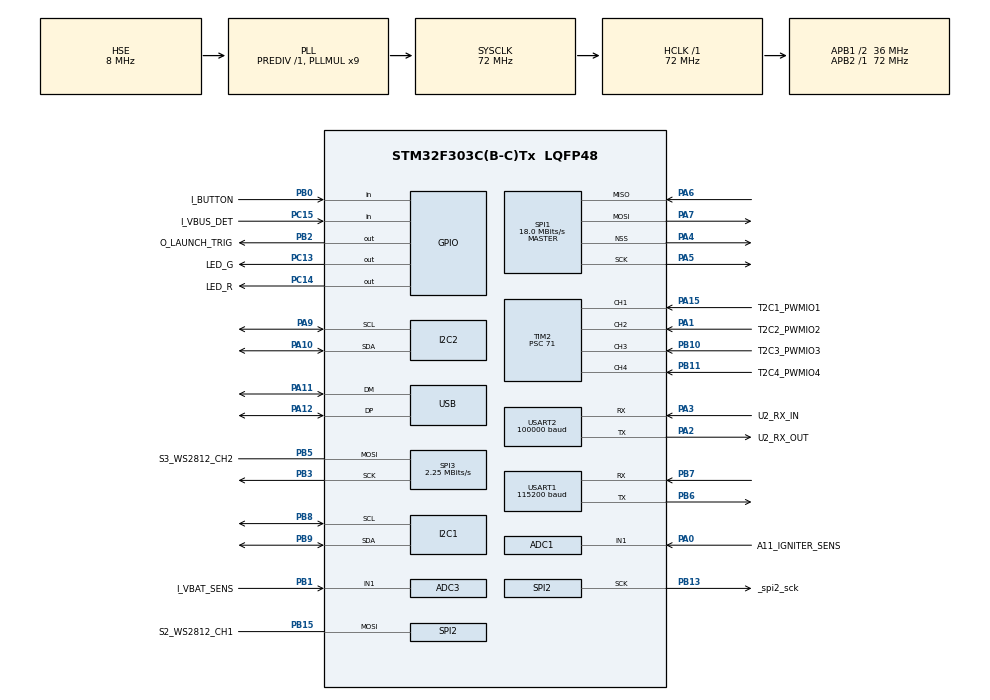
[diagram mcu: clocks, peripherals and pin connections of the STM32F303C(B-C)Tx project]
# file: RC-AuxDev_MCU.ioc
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ADC1.Channel-0\#ChannelRegularConversion=ADC_CHANNEL_TEMPSENSOR
ADC1.NbrOfConversionFlag=1
ADC1.Offset-0\#ChannelRegularConversion=0
ADC1.OffsetNumber-0\#ChannelRegularConversion=ADC_OFFSET_NONE
ADC1.Rank-0\#ChannelRegularConversion=1
ADC1.SamplingTime-0\#ChannelRegularConversion=ADC_SAMPLETIME_1CYCLE_5
ADC1.master=1
ADC3.Channel-0\#ChannelRegularConversion=ADC_CHANNEL_1
ADC3.NbrOfConversionFlag=1
ADC3.Offset-0\#ChannelRegularConversion=0
ADC3.OffsetNumber-0\#ChannelRegularConversion=ADC_OFFSET_NONE
ADC3.Rank-0\#ChannelRegularConversion=1
ADC3.SamplingTime-0\#ChannelRegularConversion=ADC_SAMPLETIME_1CYCLE_5
ADC3.SamplingTimeOPAMP-0\#ChannelRegularConversion=ADC_SAMPLETIME_61CYCLES_5
ADC3.master=1
Dma.Request0=SPI2_TX
Dma.Request1=SPI3_TX
Dma.Request2=USART2_RX
Dma.SPI2_TX.0.Direction=DMA_MEMORY_TO_PERIPH
Dma.SPI2_TX.0.Instance=DMA1_Channel5
Dma.SPI2_TX.0.MemDataAlignment=DMA_MDATAALIGN_BYTE
Dma.SPI2_TX.0.MemInc=DMA_MINC_ENABLE
Dma.SPI2_TX.0.Mode=DMA_NORMAL
Dma.SPI2_TX.0.PeriphDataAlignment=DMA_PDATAALIGN_BYTE
Dma.SPI2_TX.0.PeriphInc=DMA_PINC_DISABLE
Dma.SPI2_TX.0.Priority=DMA_PRIORITY_LOW
Dma.SPI3_TX.1.Direction=DMA_MEMORY_TO_PERIPH
Dma.SPI3_TX.1.Instance=DMA2_Channel2
Dma.SPI3_TX.1.MemDataAlignment=DMA_MDATAALIGN_BYTE
Dma.SPI3_TX.1.MemInc=DMA_MINC_ENABLE
Dma.SPI3_TX.1.Mode=DMA_NORMAL
Dma.SPI3_TX.1.PeriphDataAlignment=DMA_PDATAALIGN_BYTE
Dma.SPI3_TX.1.PeriphInc=DMA_PINC_DISABLE
Dma.SPI3_TX.1.Priority=DMA_PRIORITY_LOW
Dma.USART2_RX.2.Direction=DMA_PERIPH_TO_MEMORY
Dma.USART2_RX.2.Instance=DMA1_Channel6
Dma.USART2_RX.2.MemDataAlignment=DMA_MDATAALIGN_BYTE
Dma.USART2_RX.2.MemInc=DMA_MINC_ENABLE
Dma.USART2_RX.2.Mode=DMA_NORMAL
Dma.USART2_RX.2.PeriphDataAlignment=DMA_PDATAALIGN_BYTE
Dma.USART2_RX.2.PeriphInc=DMA_PINC_DISABLE
Dma.USART2_RX.2.Priority=DMA_PRIORITY_LOW
I2C1.Timing=0x10C18DCC
I2C2.Timing=0x10C18DCC
Mcu.Family=STM32F3
Mcu.Name=STM32F303C(B-C)Tx
Mcu.Package=LQFP48
NVIC.DMA1_Channel5_IRQn=true\:0\:0\:false\:false\:true\:true\:true\:true
NVIC.DMA1_Channel6_IRQn=true\:0\:0\:false\:false\:true\:true\:true\:true
NVIC.DMA2_Channel2_IRQn=true\:0\:0\:false\:false\:true\:true\:true\:true
NVIC.PriorityGroup=NVIC_PRIORITYGROUP_4
NVIC.TIM1_BRK_TIM15_IRQn=true\:0\:0\:false\:false\:true\:true\:true\:true
NVIC.TIM2_IRQn=true\:0\:0\:false\:false\:true\:true\:true\:true
NVIC.USART1_IRQn=true\:0\:0\:false\:false\:true\:true\:true\:true
NVIC.USART2_IRQn=true\:0\:0\:false\:false\:true\:true\:true\:true
NVIC.USB_LP_CAN_RX0_IRQn=true\:0\:0\:false\:false\:true\:false\:true\:true
PA0.GPIO_Label=A11_IGNITER_SENS
PA0.Mode=IN1-Single-Ended
PA0.Signal=ADC1_IN1
PA1.GPIO_Label=T2C2_PWMIO2
PA1.GPIO_PuPd=GPIO_PULLDOWN
PA1.Signal=S_TIM2_CH2
PA10.Mode=I2C
PA10.Signal=I2C2_SDA
PA11.Mode=Device
PA11.Signal=USB_DM
PA12.Mode=Device
PA12.Signal=USB_DP
PA13.Mode=Serial_Wire
PA13.Signal=SYS_JTMS-SWDIO
PA13.Stacked=true
PA14.Mode=Serial_Wire
PA14.Signal=SYS_JTCK-SWCLK
PA14.Stacked=true
PA15.GPIO_Label=T2C1_PWMIO1
PA15.GPIO_PuPd=GPIO_PULLDOWN
PA15.Signal=S_TIM2_CH1_ETR
PA2.GPIO_Label=U2_RX_OUT
PA2.Mode=Asynchronous
PA2.Signal=USART2_TX
PA2.Stacked=true
PA3.GPIO_Label=U2_RX_IN
PA3.Signal=SharedStack_PA3
PA3.Stacked=true
PA4.Mode=NSS_Signal_Hard_Output
PA4.Signal=SPI1_NSS
PA5.Mode=Full_Duplex_Master
PA5.Signal=SPI1_SCK
PA6.Mode=Full_Duplex_Master
PA6.Signal=SPI1_MISO
PA7.Mode=Full_Duplex_Master
PA7.Signal=SPI1_MOSI
PA9.Mode=I2C
PA9.Signal=I2C2_SCL
PB0.GPIO_Label=I_BUTTON
PB0.Signal=GPIO_Input
PB1.GPIO_Label=I_VBAT_SENS
PB1.Mode=IN1-Single-Ended
PB1.Signal=ADC3_IN1
PB10.GPIO_Label=T2C3_PWMIO3
PB10.GPIO_PuPd=GPIO_PULLDOWN
PB10.Signal=S_TIM2_CH3
PB11.GPIO_Label=T2C4_PWMIO4
PB11.GPIO_PuPd=GPIO_PULLDOWN
PB11.Signal=S_TIM2_CH4
PB13.GPIO_Label=_spi2_sck
PB13.Mode=Simplex_Bidirectional_Master
PB13.Signal=SPI2_SCK
PB13.Stacked=true
PB15.GPIO_Label=S2_WS2812_CH1
PB15.Mode=Simplex_Bidirectional_Master
PB15.Signal=SPI2_MOSI
PB2.GPIO_Label=O_LAUNCH_TRIG
PB2.GPIO_PuPd=GPIO_PULLDOWN
PB2.Signal=GPIO_Output
PB3.Signal=SharedStack_PB3
PB3.Stacked=true
PB5.GPIO_Label=S3_WS2812_CH2
PB5.Mode=Simplex_Bidirectional_Master
PB5.Signal=SPI3_MOSI
PB6.Mode=Asynchronous
PB6.Signal=USART1_TX
PB7.Mode=Asynchronous
PB7.Signal=USART1_RX
PB8.Mode=I2C
PB8.Signal=I2C1_SCL
PB9.Mode=I2C
PB9.Signal=I2C1_SDA
PC13.GPIO_Label=LED_G
PC13.GPIO_ModeDefaultOutputPP=GPIO_MODE_OUTPUT_OD
PC13.GPIO_PuPd=GPIO_NOPULL
PC13.Signal=GPIO_Output
PC14-OSC32_IN.GPIO_Label=LED_R
PC14-OSC32_IN.GPIO_ModeDefaultOutputPP=GPIO_MODE_OUTPUT_OD
PC14-OSC32_IN.GPIO_PuPd=GPIO_NOPULL
PC14-OSC32_IN.Signal=GPIO_Output
PC15-OSC32_OUT.GPIO_Label=I_VBUS_DET
PC15-OSC32_OUT.GPIO_PuPd=GPIO_PULLDOWN
PC15-OSC32_OUT.Signal=GPIO_Input
PF0-OSC_IN.Mode=HSE-External-Oscillator
PF0-OSC_IN.Signal=RCC_OSC_IN
PF1-OSC_OUT.Mode=HSE-External-Oscillator
PF1-OSC_OUT.Signal=RCC_OSC_OUT
ProjectManager.HeapSize=0x200
ProjectManager.StackSize=0x400
ProjectManager.TargetToolchain=CMake
RCC.AHBFreq_Value=72000000
RCC.APB1CLKDivider=RCC_HCLK_DIV2
RCC.APB1Freq_Value=36000000
RCC.APB1TimFreq_Value=72000000
RCC.APB2Freq_Value=72000000
RCC.APB2TimFreq_Value=72000000
RCC.CortexFreq_Value=72000000
RCC.HCLKFreq_Value=72000000
RCC.HSE_VALUE=8000000
RCC.HSI_VALUE=8000000
RCC.I2c1ClockSelection=RCC_I2C1CLKSOURCE_SYSCLK
RCC.I2c2ClockSelection=RCC_I2C2CLKSOURCE_SYSCLK
RCC.LSE_VALUE=32768
RCC.PLLMUL=RCC_PLL_MUL9
RCC.PRESCALERUSB=RCC_USBCLKSOURCE_PLL_DIV1_5
RCC.SYSCLKFreq_VALUE=72000000
RCC.SYSCLKSourceVirtual=RCC_SYSCLKSOURCE_PLLCLK
RCC.USBFreq_Value=48000000
RCC.Usart1ClockSelection=RCC_USART1CLKSOURCE_SYSCLK
RCC.Usart2ClockSelection=RCC_USART2CLKSOURCE_SYSCLK
RCC.Usart3ClockSelection=RCC_USART3CLKSOURCE_SYSCLK
SH.S_TIM2_CH1_ETR.0=TIM2_CH1,Input_Capture1_from_TI1
SH.S_TIM2_CH2.0=TIM2_CH2,Input_Capture2_from_TI2
SH.S_TIM2_CH3.0=TIM2_CH3,Input_Capture3_from_TI3
SH.S_TIM2_CH4.0=TIM2_CH4,Input_Capture4_from_TI4
SH.SharedStack_PA3.0=TIM15_CH2
SH.SharedStack_PA3.1=USART2_RX,Asynchronous
SH.SharedStack_PB3.0=SYS_JTDO-TRACESWO
SH.SharedStack_PB3.1=SPI3_SCK,Simplex_Bidirectional_Master
SPI1.BaudRatePrescaler=SPI_BAUDRATEPRESCALER_4
SPI1.CalculateBaudRate=18.0 MBits/s
SPI1.Direction=SPI_DIRECTION_2LINES
SPI1.Mode=SPI_MODE_MASTER
SPI1.VirtualNSS=VM_NSSHARD
SPI1.VirtualType=VM_MASTER
SPI2.BaudRatePrescaler=SPI_BAUDRATEPRESCALER_16
SPI2.CalculateBaudRate=2.25 MBits/s
SPI2.DataSize=SPI_DATASIZE_8BIT
SPI2.Direction=SPI_DIRECTION_1LINE
SPI2.Mode=SPI_MODE_MASTER
SPI2.NSSPMode=SPI_NSS_PULSE_DISABLE
SPI2.VirtualType=VM_MASTER
SPI3.BaudRatePrescaler=SPI_BAUDRATEPRESCALER_16
SPI3.CalculateBaudRate=2.25 MBits/s
SPI3.DataSize=SPI_DATASIZE_8BIT
SPI3.Direction=SPI_DIRECTION_1LINE
SPI3.Mode=SPI_MODE_MASTER
SPI3.NSSPMode=SPI_NSS_PULSE_DISABLE
SPI3.VirtualType=VM_MASTER
TIM15.Channel-Output\ Compare2\ No\ Output=TIM_CHANNEL_2
TIM15.Prescaler=71
TIM2.Channel-Input_Capture1_from_TI1=TIM_CHANNEL_1
TIM2.Channel-Input_Capture2_from_TI2=TIM_CHANNEL_2
TIM2.Channel-Input_Capture3_from_TI3=TIM_CHANNEL_3
TIM2.Channel-Input_Capture4_from_TI4=TIM_CHANNEL_4
TIM2.Prescaler=71
USART1.BaudRate=115200
USART1.VirtualMode-Asynchronous=VM_ASYNC
USART2.BaudRate=100000
USART2.Mode=MODE_RX
USART2.Parity=PARITY_EVEN
USART2.RxPinLevelInvertParam=ADVFEATURE_RXINV_ENABLE
USART2.StopBits=STOPBITS_2
USART2.VirtualMode-Asynchronous=VM_ASYNC
USART2.WordLength=WORDLENGTH_9B
USB_DEVICE.CLASS_NAME_FS=CDC
USB_DEVICE.VirtualMode=Cdc
USB_DEVICE.VirtualModeFS=Cdc_FS
VP_ADC1_TempSens_Input.Mode=IN-TempSens
VP_CRC_VS_CRC.Mode=CRC_Activate
VP_RTC_VS_RTC_Activate.Mode=RTC_Enabled
VP_TIM15_VS_ClockSourceINT.Mode=Internal
VP_TIM15_VS_no_output2.Mode=Output Compare2 No Output
VP_TIM2_VS_ClockSourceINT.Mode=Internal
VP_USB_DEVICE_VS_USB_DEVICE_CDC_FS.Mode=CDC_FS
board=custom

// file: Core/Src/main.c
/* USER CODE BEGIN Header */
/**
  ******************************************************************************
  * @file           : main.c
  * @brief          : Main program body
  ******************************************************************************
  * @attention
  *
  * Copyright (c) 2026 STMicroelectronics.
  * All rights reserved.
  *
  * This software is licensed under terms that can be found in the LICENSE file
  * in the root directory of this software component.
  * If no LICENSE file comes with this software, it is provided AS-IS.
  *
  ******************************************************************************
  */
/* USER CODE END Header */
#include "main.h"
#include "usb_device.h"

ADC_HandleTypeDef hadc1;
ADC_HandleTypeDef hadc3;

CRC_HandleTypeDef hcrc;

I2C_HandleTypeDef hi2c1;
I2C_HandleTypeDef hi2c2;

RTC_HandleTypeDef hrtc;

SPI_HandleTypeDef hspi1;
SPI_HandleTypeDef hspi2;
SPI_HandleTypeDef hspi3;
DMA_HandleTypeDef hdma_spi2_tx;
DMA_HandleTypeDef hdma_spi3_tx;

TIM_HandleTypeDef htim2;
TIM_HandleTypeDef htim15;

UART_HandleTypeDef huart1;
UART_HandleTypeDef huart2;
DMA_HandleTypeDef hdma_usart2_rx;

/* USER CODE BEGIN PV */

// MYCUST: code entry points
void main_loop();

/* USER CODE END PV */

void SystemClock_Config(void);
static void MX_GPIO_Init(void);
static void MX_DMA_Init(void);
static void MX_USART1_UART_Init(void);
static void MX_ADC1_Init(void);
static void MX_RTC_Init(void);
static void MX_SPI1_Init(void);
static void MX_I2C1_Init(void);
static void MX_TIM2_Init(void);
static void MX_SPI2_Init(void);
static void MX_I2C2_Init(void);
static void MX_SPI3_Init(void);
static void MX_TIM15_Init(void);
static void MX_CRC_Init(void);
static void MX_USART2_UART_Init(void);
static void MX_ADC3_Init(void);

int main(void)
{

  /* MCU Configuration--------------------------------------------------------*/

  /* Reset of all peripherals, Initializes the Flash interface and the Systick. */
  HAL_Init();

  /* Configure the system clock */
  SystemClock_Config();

  /* USER CODE BEGIN SysInit */

  // MYCUST: Force USB re-enumeration by pulling D+ low
  __HAL_RCC_GPIOA_CLK_ENABLE();
  GPIO_InitTypeDef GPIO_InitStruct = {0};
  GPIO_InitStruct.Pin = GPIO_PIN_12;  // USB D+ pin
  GPIO_InitStruct.Mode = GPIO_MODE_OUTPUT_PP;
  GPIO_InitStruct.Pull = GPIO_NOPULL;
  GPIO_InitStruct.Speed = GPIO_SPEED_FREQ_LOW;
  HAL_GPIO_Init(GPIOA, &GPIO_InitStruct);
  HAL_GPIO_WritePin(GPIOA, GPIO_PIN_12, GPIO_PIN_RESET);  // Pull D+ low
  HAL_Delay(50);  // Hold low for 50ms to ensure host detects disconnect

  /* USER CODE END SysInit */

  /* Initialize all configured peripherals */
  MX_GPIO_Init();
  MX_DMA_Init();
  MX_USART1_UART_Init();
  MX_USB_DEVICE_Init();
  MX_ADC1_Init();
  MX_RTC_Init();
  MX_SPI1_Init();
  MX_I2C1_Init();
  MX_TIM2_Init();
  MX_SPI2_Init();
  MX_I2C2_Init();
  MX_SPI3_Init();
  MX_TIM15_Init();
  MX_CRC_Init();
  MX_USART2_UART_Init();
  MX_ADC3_Init();
  /* USER CODE BEGIN 2 */

  // MYCUST: entry point
  main_loop();

  /* USER CODE END 2 */

  /* Infinite loop */
  while (1)
  {

  }
}

void SystemClock_Config(void)
{
  RCC_OscInitTypeDef RCC_OscInitStruct = {0};
  RCC_ClkInitTypeDef RCC_ClkInitStruct = {0};
  RCC_PeriphCLKInitTypeDef PeriphClkInit = {0};

  /** Initializes the RCC Oscillators according to the specified parameters
  * in the RCC_OscInitTypeDef structure.
  */
  RCC_OscInitStruct.OscillatorType = RCC_OSCILLATORTYPE_LSI|RCC_OSCILLATORTYPE_HSE;
  RCC_OscInitStruct.HSEState = RCC_HSE_ON;
  RCC_OscInitStruct.HSEPredivValue = RCC_HSE_PREDIV_DIV1;
  RCC_OscInitStruct.HSIState = RCC_HSI_ON;
  RCC_OscInitStruct.LSIState = RCC_LSI_ON;
  RCC_OscInitStruct.PLL.PLLState = RCC_PLL_ON;
  RCC_OscInitStruct.PLL.PLLSource = RCC_PLLSOURCE_HSE;
  RCC_OscInitStruct.PLL.PLLMUL = RCC_PLL_MUL9;
  if (HAL_RCC_OscConfig(&RCC_OscInitStruct) != HAL_OK)
  {
    Error_Handler();
  }

  /** Initializes the CPU, AHB and APB buses clocks
  */
  RCC_ClkInitStruct.ClockType = RCC_CLOCKTYPE_HCLK|RCC_CLOCKTYPE_SYSCLK
                              |RCC_CLOCKTYPE_PCLK1|RCC_CLOCKTYPE_PCLK2;
  RCC_ClkInitStruct.SYSCLKSource = RCC_SYSCLKSOURCE_PLLCLK;
  RCC_ClkInitStruct.AHBCLKDivider = RCC_SYSCLK_DIV1;
  RCC_ClkInitStruct.APB1CLKDivider = RCC_HCLK_DIV2;
  RCC_ClkInitStruct.APB2CLKDivider = RCC_HCLK_DIV1;

  if (HAL_RCC_ClockConfig(&RCC_ClkInitStruct, FLASH_LATENCY_2) != HAL_OK)
  {
    Error_Handler();
  }
  PeriphClkInit.PeriphClockSelection = RCC_PERIPHCLK_USB|RCC_PERIPHCLK_USART1
                              |RCC_PERIPHCLK_USART2|RCC_PERIPHCLK_I2C1
                              |RCC_PERIPHCLK_I2C2|RCC_PERIPHCLK_RTC
                              |RCC_PERIPHCLK_ADC12|RCC_PERIPHCLK_ADC34;
  PeriphClkInit.Usart1ClockSelection = RCC_USART1CLKSOURCE_SYSCLK;
  PeriphClkInit.Usart2ClockSelection = RCC_USART2CLKSOURCE_SYSCLK;
  PeriphClkInit.Adc12ClockSelection = RCC_ADC12PLLCLK_DIV1;
  PeriphClkInit.Adc34ClockSelection = RCC_ADC34PLLCLK_DIV1;
  PeriphClkInit.I2c1ClockSelection = RCC_I2C1CLKSOURCE_SYSCLK;
  PeriphClkInit.I2c2ClockSelection = RCC_I2C2CLKSOURCE_SYSCLK;
  PeriphClkInit.RTCClockSelection = RCC_RTCCLKSOURCE_LSI;
  PeriphClkInit.USBClockSelection = RCC_USBCLKSOURCE_PLL_DIV1_5;
  if (HAL_RCCEx_PeriphCLKConfig(&PeriphClkInit) != HAL_OK)
  {
    Error_Handler();
  }
}

static void MX_ADC1_Init(void)
{

  ADC_MultiModeTypeDef multimode = {0};
  ADC_ChannelConfTypeDef sConfig = {0};

  /** Common config
  */
  hadc1.Instance = ADC1;
  hadc1.Init.ClockPrescaler = ADC_CLOCK_ASYNC_DIV1;
  hadc1.Init.Resolution = ADC_RESOLUTION_12B;
  hadc1.Init.ScanConvMode = ADC_SCAN_DISABLE;
  hadc1.Init.ContinuousConvMode = DISABLE;
  hadc1.Init.DiscontinuousConvMode = DISABLE;
  hadc1.Init.ExternalTrigConvEdge = ADC_EXTERNALTRIGCONVEDGE_NONE;
  hadc1.Init.ExternalTrigConv = ADC_SOFTWARE_START;
  hadc1.Init.DataAlign = ADC_DATAALIGN_RIGHT;
  hadc1.Init.NbrOfConversion = 1;
  hadc1.Init.DMAContinuousRequests = DISABLE;
  hadc1.Init.EOCSelection = ADC_EOC_SINGLE_CONV;
  hadc1.Init.LowPowerAutoWait = DISABLE;
  hadc1.Init.Overrun = ADC_OVR_DATA_OVERWRITTEN;
  if (HAL_ADC_Init(&hadc1) != HAL_OK)
  {
    Error_Handler();
  }

  /** Configure the ADC multi-mode
  */
  multimode.Mode = ADC_MODE_INDEPENDENT;
  if (HAL_ADCEx_MultiModeConfigChannel(&hadc1, &multimode) != HAL_OK)
  {
    Error_Handler();
  }

  /** Configure Regular Channel
  */
  sConfig.Channel = ADC_CHANNEL_TEMPSENSOR;
  sConfig.Rank = ADC_REGULAR_RANK_1;
  sConfig.SingleDiff = ADC_SINGLE_ENDED;
  sConfig.SamplingTime = ADC_SAMPLETIME_1CYCLE_5;
  sConfig.OffsetNumber = ADC_OFFSET_NONE;
  sConfig.Offset = 0;
  if (HAL_ADC_ConfigChannel(&hadc1, &sConfig) != HAL_OK)
  {
    Error_Handler();
  }

}

static void MX_ADC3_Init(void)
{

  ADC_MultiModeTypeDef multimode = {0};
  ADC_ChannelConfTypeDef sConfig = {0};

  /** Common config
  */
  hadc3.Instance = ADC3;
  hadc3.Init.ClockPrescaler = ADC_CLOCK_ASYNC_DIV1;
  hadc3.Init.Resolution = ADC_RESOLUTION_12B;
  hadc3.Init.ScanConvMode = ADC_SCAN_DISABLE;
  hadc3.Init.ContinuousConvMode = DISABLE;
  hadc3.Init.DiscontinuousConvMode = DISABLE;
  hadc3.Init.ExternalTrigConvEdge = ADC_EXTERNALTRIGCONVEDGE_NONE;
  hadc3.Init.ExternalTrigConv = ADC_SOFTWARE_START;
  hadc3.Init.DataAlign = ADC_DATAALIGN_RIGHT;
  hadc3.Init.NbrOfConversion = 1;
  hadc3.Init.DMAContinuousRequests = DISABLE;
  hadc3.Init.EOCSelection = ADC_EOC_SINGLE_CONV;
  hadc3.Init.LowPowerAutoWait = DISABLE;
  hadc3.Init.Overrun = ADC_OVR_DATA_OVERWRITTEN;
  if (HAL_ADC_Init(&hadc3) != HAL_OK)
  {
    Error_Handler();
  }

  /** Configure the ADC multi-mode
  */
  multimode.Mode = ADC_MODE_INDEPENDENT;
  if (HAL_ADCEx_MultiModeConfigChannel(&hadc3, &multimode) != HAL_OK)
  {
    Error_Handler();
  }

  /** Configure Regular Channel
  */
  sConfig.Channel = ADC_CHANNEL_1;
  sConfig.Rank = ADC_REGULAR_RANK_1;
  sConfig.SingleDiff = ADC_SINGLE_ENDED;
  sConfig.SamplingTime = ADC_SAMPLETIME_1CYCLE_5;
  sConfig.OffsetNumber = ADC_OFFSET_NONE;
  sConfig.Offset = 0;
  if (HAL_ADC_ConfigChannel(&hadc3, &sConfig) != HAL_OK)
  {
    Error_Handler();
  }

}

static void MX_CRC_Init(void)
{

  hcrc.Instance = CRC;
  hcrc.Init.DefaultPolynomialUse = DEFAULT_POLYNOMIAL_ENABLE;
  hcrc.Init.DefaultInitValueUse = DEFAULT_INIT_VALUE_ENABLE;
  hcrc.Init.InputDataInversionMode = CRC_INPUTDATA_INVERSION_NONE;
  hcrc.Init.OutputDataInversionMode = CRC_OUTPUTDATA_INVERSION_DISABLE;
  hcrc.InputDataFormat = CRC_INPUTDATA_FORMAT_BYTES;
  if (HAL_CRC_Init(&hcrc) != HAL_OK)
  {
    Error_Handler();
  }

}

static void MX_I2C1_Init(void)
{

  hi2c1.Instance = I2C1;
  hi2c1.Init.Timing = 0x10C18DCC;
  hi2c1.Init.OwnAddress1 = 0;
  hi2c1.Init.AddressingMode = I2C_ADDRESSINGMODE_7BIT;
  hi2c1.Init.DualAddressMode = I2C_DUALADDRESS_DISABLE;
  hi2c1.Init.OwnAddress2 = 0;
  hi2c1.Init.OwnAddress2Masks = I2C_OA2_NOMASK;
  hi2c1.Init.GeneralCallMode = I2C_GENERALCALL_DISABLE;
  hi2c1.Init.NoStretchMode = I2C_NOSTRETCH_DISABLE;
  if (HAL_I2C_Init(&hi2c1) != HAL_OK)
  {
    Error_Handler();
  }

  /** Configure Analogue filter
  */
  if (HAL_I2CEx_ConfigAnalogFilter(&hi2c1, I2C_ANALOGFILTER_ENABLE) != HAL_OK)
  {
    Error_Handler();
  }

  /** Configure Digital filter
  */
  if (HAL_I2CEx_ConfigDigitalFilter(&hi2c1, 0) != HAL_OK)
  {
    Error_Handler();
  }

}

static void MX_I2C2_Init(void)
{

  hi2c2.Instance = I2C2;
  hi2c2.Init.Timing = 0x10C18DCC;
  hi2c2.Init.OwnAddress1 = 0;
  hi2c2.Init.AddressingMode = I2C_ADDRESSINGMODE_7BIT;
  hi2c2.Init.DualAddressMode = I2C_DUALADDRESS_DISABLE;
  hi2c2.Init.OwnAddress2 = 0;
  hi2c2.Init.OwnAddress2Masks = I2C_OA2_NOMASK;
  hi2c2.Init.GeneralCallMode = I2C_GENERALCALL_DISABLE;
  hi2c2.Init.NoStretchMode = I2C_NOSTRETCH_DISABLE;
  if (HAL_I2C_Init(&hi2c2) != HAL_OK)
  {
    Error_Handler();
  }

  /** Configure Analogue filter
  */
  if (HAL_I2CEx_ConfigAnalogFilter(&hi2c2, I2C_ANALOGFILTER_ENABLE) != HAL_OK)
  {
    Error_Handler();
  }

  /** Configure Digital filter
  */
  if (HAL_I2CEx_ConfigDigitalFilter(&hi2c2, 0) != HAL_OK)
  {
    Error_Handler();
  }

}

static void MX_RTC_Init(void)
{

  /** Initialize RTC Only
  */
  hrtc.Instance = RTC;
  hrtc.Init.HourFormat = RTC_HOURFORMAT_24;
  hrtc.Init.AsynchPrediv = 127;
  hrtc.Init.SynchPrediv = 255;
  hrtc.Init.OutPut = RTC_OUTPUT_DISABLE;
  hrtc.Init.OutPutPolarity = RTC_OUTPUT_POLARITY_HIGH;
  hrtc.Init.OutPutType = RTC_OUTPUT_TYPE_OPENDRAIN;
  if (HAL_RTC_Init(&hrtc) != HAL_OK)
  {
    Error_Handler();
  }

}

static void MX_SPI1_Init(void)
{

  /* SPI1 parameter configuration*/
  hspi1.Instance = SPI1;
  hspi1.Init.Mode = SPI_MODE_MASTER;
  hspi1.Init.Direction = SPI_DIRECTION_2LINES;
  hspi1.Init.DataSize = SPI_DATASIZE_4BIT;
  hspi1.Init.CLKPolarity = SPI_POLARITY_LOW;
  hspi1.Init.CLKPhase = SPI_PHASE_1EDGE;
  hspi1.Init.NSS = SPI_NSS_HARD_OUTPUT;
  hspi1.Init.BaudRatePrescaler = SPI_BAUDRATEPRESCALER_4;
  hspi1.Init.FirstBit = SPI_FIRSTBIT_MSB;
  hspi1.Init.TIMode = SPI_TIMODE_DISABLE;
  hspi1.Init.CRCCalculation = SPI_CRCCALCULATION_DISABLE;
  hspi1.Init.CRCPolynomial = 7;
  hspi1.Init.CRCLength = SPI_CRC_LENGTH_DATASIZE;
  hspi1.Init.NSSPMode = SPI_NSS_PULSE_ENABLE;
  if (HAL_SPI_Init(&hspi1) != HAL_OK)
  {
    Error_Handler();
  }

}

static void MX_SPI2_Init(void)
{

  /* SPI2 parameter configuration*/
  hspi2.Instance = SPI2;
  hspi2.Init.Mode = SPI_MODE_MASTER;
  hspi2.Init.Direction = SPI_DIRECTION_1LINE;
  hspi2.Init.DataSize = SPI_DATASIZE_8BIT;
  hspi2.Init.CLKPolarity = SPI_POLARITY_LOW;
  hspi2.Init.CLKPhase = SPI_PHASE_1EDGE;
  hspi2.Init.NSS = SPI_NSS_SOFT;
  hspi2.Init.BaudRatePrescaler = SPI_BAUDRATEPRESCALER_16;
  hspi2.Init.FirstBit = SPI_FIRSTBIT_MSB;
  hspi2.Init.TIMode = SPI_TIMODE_DISABLE;
  hspi2.Init.CRCCalculation = SPI_CRCCALCULATION_DISABLE;
  hspi2.Init.CRCPolynomial = 7;
  hspi2.Init.CRCLength = SPI_CRC_LENGTH_DATASIZE;
  hspi2.Init.NSSPMode = SPI_NSS_PULSE_DISABLE;
  if (HAL_SPI_Init(&hspi2) != HAL_OK)
  {
    Error_Handler();
  }

}

static void MX_SPI3_Init(void)
{

  /* SPI3 parameter configuration*/
  hspi3.Instance = SPI3;
  hspi3.Init.Mode = SPI_MODE_MASTER;
  hspi3.Init.Direction = SPI_DIRECTION_1LINE;
  hspi3.Init.DataSize = SPI_DATASIZE_8BIT;
  hspi3.Init.CLKPolarity = SPI_POLARITY_LOW;
  hspi3.Init.CLKPhase = SPI_PHASE_1EDGE;
  hspi3.Init.NSS = SPI_NSS_SOFT;
  hspi3.Init.BaudRatePrescaler = SPI_BAUDRATEPRESCALER_16;
  hspi3.Init.FirstBit = SPI_FIRSTBIT_MSB;
  hspi3.Init.TIMode = SPI_TIMODE_DISABLE;
  hspi3.Init.CRCCalculation = SPI_CRCCALCULATION_DISABLE;
  hspi3.Init.CRCPolynomial = 7;
  hspi3.Init.CRCLength = SPI_CRC_LENGTH_DATASIZE;
  hspi3.Init.NSSPMode = SPI_NSS_PULSE_DISABLE;
  if (HAL_SPI_Init(&hspi3) != HAL_OK)
  {
    Error_Handler();
  }

}

static void MX_TIM2_Init(void)
{

  TIM_ClockConfigTypeDef sClockSourceConfig = {0};
  TIM_MasterConfigTypeDef sMasterConfig = {0};
  TIM_IC_InitTypeDef sConfigIC = {0};

  htim2.Instance = TIM2;
  htim2.Init.Prescaler = 71;
  htim2.Init.CounterMode = TIM_COUNTERMODE_UP;
  htim2.Init.Period = 4294967295;
  htim2.Init.ClockDivision = TIM_CLOCKDIVISION_DIV1;
  htim2.Init.AutoReloadPreload = TIM_AUTORELOAD_PRELOAD_DISABLE;
  if (HAL_TIM_Base_Init(&htim2) != HAL_OK)
  {
    Error_Handler();
  }
  sClockSourceConfig.ClockSource = TIM_CLOCKSOURCE_INTERNAL;
  if (HAL_TIM_ConfigClockSource(&htim2, &sClockSourceConfig) != HAL_OK)
  {
    Error_Handler();
  }
  if (HAL_TIM_IC_Init(&htim2) != HAL_OK)
  {
    Error_Handler();
  }
  sMasterConfig.MasterOutputTrigger = TIM_TRGO_RESET;
  sMasterConfig.MasterSlaveMode = TIM_MASTERSLAVEMODE_DISABLE;
  if (HAL_TIMEx_MasterConfigSynchronization(&htim2, &sMasterConfig) != HAL_OK)
  {
    Error_Handler();
  }
  sConfigIC.ICPolarity = TIM_INPUTCHANNELPOLARITY_RISING;
  sConfigIC.ICSelection = TIM_ICSELECTION_DIRECTTI;
  sConfigIC.ICPrescaler = TIM_ICPSC_DIV1;
  sConfigIC.ICFilter = 0;
  if (HAL_TIM_IC_ConfigChannel(&htim2, &sConfigIC, TIM_CHANNEL_1) != HAL_OK)
  {
    Error_Handler();
  }
  if (HAL_TIM_IC_ConfigChannel(&htim2, &sConfigIC, TIM_CHANNEL_2) != HAL_OK)
  {
    Error_Handler();
  }
  if (HAL_TIM_IC_ConfigChannel(&htim2, &sConfigIC, TIM_CHANNEL_3) != HAL_OK)
  {
    Error_Handler();
  }
  if (HAL_TIM_IC_ConfigChannel(&htim2, &sConfigIC, TIM_CHANNEL_4) != HAL_OK)
  {
    Error_Handler();
  }

}

static void MX_TIM15_Init(void)
{

  TIM_ClockConfigTypeDef sClockSourceConfig = {0};
  TIM_MasterConfigTypeDef sMasterConfig = {0};
  TIM_OC_InitTypeDef sConfigOC = {0};
  TIM_BreakDeadTimeConfigTypeDef sBreakDeadTimeConfig = {0};

  htim15.Instance = TIM15;
  htim15.Init.Prescaler = 71;
  htim15.Init.CounterMode = TIM_COUNTERMODE_UP;
  htim15.Init.Period = 65535;
  htim15.Init.ClockDivision = TIM_CLOCKDIVISION_DIV1;
  htim15.Init.RepetitionCounter = 0;
  htim15.Init.AutoReloadPreload = TIM_AUTORELOAD_PRELOAD_DISABLE;
  if (HAL_TIM_Base_Init(&htim15) != HAL_OK)
  {
    Error_Handler();
  }
  sClockSourceConfig.ClockSource = TIM_CLOCKSOURCE_INTERNAL;
  if (HAL_TIM_ConfigClockSource(&htim15, &sClockSourceConfig) != HAL_OK)
  {
    Error_Handler();
  }
  if (HAL_TIM_OC_Init(&htim15) != HAL_OK)
  {
    Error_Handler();
  }
  sMasterConfig.MasterOutputTrigger = TIM_TRGO_RESET;
  sMasterConfig.MasterSlaveMode = TIM_MASTERSLAVEMODE_DISABLE;
  if (HAL_TIMEx_MasterConfigSynchronization(&htim15, &sMasterConfig) != HAL_OK)
  {
    Error_Handler();
  }
  sConfigOC.OCMode = TIM_OCMODE_TIMING;
  sConfigOC.Pulse = 0;
  sConfigOC.OCPolarity = TIM_OCPOLARITY_HIGH;
  sConfigOC.OCNPolarity = TIM_OCNPOLARITY_HIGH;
  sConfigOC.OCFastMode = TIM_OCFAST_DISABLE;
  sConfigOC.OCIdleState = TIM_OCIDLESTATE_RESET;
  sConfigOC.OCNIdleState = TIM_OCNIDLESTATE_RESET;
  if (HAL_TIM_OC_ConfigChannel(&htim15, &sConfigOC, TIM_CHANNEL_2) != HAL_OK)
  {
    Error_Handler();
  }
  sBreakDeadTimeConfig.OffStateRunMode = TIM_OSSR_DISABLE;
  sBreakDeadTimeConfig.OffStateIDLEMode = TIM_OSSI_DISABLE;
  sBreakDeadTimeConfig.LockLevel = TIM_LOCKLEVEL_OFF;
  sBreakDeadTimeConfig.DeadTime = 0;
  sBreakDeadTimeConfig.BreakState = TIM_BREAK_DISABLE;
  sBreakDeadTimeConfig.BreakPolarity = TIM_BREAKPOLARITY_HIGH;
  sBreakDeadTimeConfig.BreakFilter = 0;
  sBreakDeadTimeConfig.AutomaticOutput = TIM_AUTOMATICOUTPUT_DISABLE;
  if (HAL_TIMEx_ConfigBreakDeadTime(&htim15, &sBreakDeadTimeConfig) != HAL_OK)
  {
    Error_Handler();
  }

}

static void MX_USART1_UART_Init(void)
{

  huart1.Instance = USART1;
  huart1.Init.BaudRate = 115200;
  huart1.Init.WordLength = UART_WORDLENGTH_8B;
  huart1.Init.StopBits = UART_STOPBITS_1;
  huart1.Init.Parity = UART_PARITY_NONE;
  huart1.Init.Mode = UART_MODE_TX_RX;
  huart1.Init.HwFlowCtl = UART_HWCONTROL_NONE;
  huart1.Init.OverSampling = UART_OVERSAMPLING_16;
  huart1.Init.OneBitSampling = UART_ONE_BIT_SAMPLE_DISABLE;
  huart1.AdvancedInit.AdvFeatureInit = UART_ADVFEATURE_NO_INIT;
  if (HAL_UART_Init(&huart1) != HAL_OK)
  {
    Error_Handler();
  }

}

static void MX_USART2_UART_Init(void)
{

  huart2.Instance = USART2;
  huart2.Init.BaudRate = 100000;
  huart2.Init.WordLength = UART_WORDLENGTH_9B;
  huart2.Init.StopBits = UART_STOPBITS_2;
  huart2.Init.Parity = UART_PARITY_EVEN;
  huart2.Init.Mode = UART_MODE_RX;
  huart2.Init.HwFlowCtl = UART_HWCONTROL_NONE;
  huart2.Init.OverSampling = UART_OVERSAMPLING_16;
  huart2.Init.OneBitSampling = UART_ONE_BIT_SAMPLE_DISABLE;
  huart2.AdvancedInit.AdvFeatureInit = UART_ADVFEATURE_RXINVERT_INIT;
  huart2.AdvancedInit.RxPinLevelInvert = UART_ADVFEATURE_RXINV_ENABLE;
  if (HAL_UART_Init(&huart2) != HAL_OK)
  {
    Error_Handler();
  }

}

static void MX_DMA_Init(void)
{

  /* DMA controller clock enable */
  __HAL_RCC_DMA1_CLK_ENABLE();
  __HAL_RCC_DMA2_CLK_ENABLE();

  /* DMA interrupt init */
  /* DMA1_Channel5_IRQn interrupt configuration */
  HAL_NVIC_SetPriority(DMA1_Channel5_IRQn, 0, 0);
  HAL_NVIC_EnableIRQ(DMA1_Channel5_IRQn);
  /* DMA1_Channel6_IRQn interrupt configuration */
  HAL_NVIC_SetPriority(DMA1_Channel6_IRQn, 0, 0);
  HAL_NVIC_EnableIRQ(DMA1_Channel6_IRQn);
  /* DMA2_Channel2_IRQn interrupt configuration */
  HAL_NVIC_SetPriority(DMA2_Channel2_IRQn, 0, 0);
  HAL_NVIC_EnableIRQ(DMA2_Channel2_IRQn);

}

static void MX_GPIO_Init(void)
{
  GPIO_InitTypeDef GPIO_InitStruct = {0};

  /* GPIO Ports Clock Enable */
  __HAL_RCC_GPIOC_CLK_ENABLE();
  __HAL_RCC_GPIOF_CLK_ENABLE();
  __HAL_RCC_GPIOA_CLK_ENABLE();
  __HAL_RCC_GPIOB_CLK_ENABLE();

  /*Configure GPIO pin Output Level */
  HAL_GPIO_WritePin(GPIOC, LED_G_Pin|LED_R_Pin, GPIO_PIN_RESET);

  /*Configure GPIO pin Output Level */
  HAL_GPIO_WritePin(O_LAUNCH_TRIG_GPIO_Port, O_LAUNCH_TRIG_Pin, GPIO_PIN_RESET);

  /*Configure GPIO pins : LED_G_Pin LED_R_Pin */
  GPIO_InitStruct.Pin = LED_G_Pin|LED_R_Pin;
  GPIO_InitStruct.Mode = GPIO_MODE_OUTPUT_OD;
  GPIO_InitStruct.Pull = GPIO_NOPULL;
  GPIO_InitStruct.Speed = GPIO_SPEED_FREQ_LOW;
  HAL_GPIO_Init(GPIOC, &GPIO_InitStruct);

  /*Configure GPIO pin : I_VBUS_DET_Pin */
  GPIO_InitStruct.Pin = I_VBUS_DET_Pin;
  GPIO_InitStruct.Mode = GPIO_MODE_INPUT;
  GPIO_InitStruct.Pull = GPIO_PULLDOWN;
  HAL_GPIO_Init(I_VBUS_DET_GPIO_Port, &GPIO_InitStruct);

  /*Configure GPIO pin : I_BUTTON_Pin */
  GPIO_InitStruct.Pin = I_BUTTON_Pin;
  GPIO_InitStruct.Mode = GPIO_MODE_INPUT;
  GPIO_InitStruct.Pull = GPIO_NOPULL;
  HAL_GPIO_Init(I_BUTTON_GPIO_Port, &GPIO_InitStruct);

  /*Configure GPIO pin : O_LAUNCH_TRIG_Pin */
  GPIO_InitStruct.Pin = O_LAUNCH_TRIG_Pin;
  GPIO_InitStruct.Mode = GPIO_MODE_OUTPUT_PP;
  GPIO_InitStruct.Pull = GPIO_PULLDOWN;
  GPIO_InitStruct.Speed = GPIO_SPEED_FREQ_LOW;
  HAL_GPIO_Init(O_LAUNCH_TRIG_GPIO_Port, &GPIO_InitStruct);

  /*Configure GPIO pins : PB12 PB14 PB4 */
  GPIO_InitStruct.Pin = GPIO_PIN_12|GPIO_PIN_14|GPIO_PIN_4;
  GPIO_InitStruct.Mode = GPIO_MODE_ANALOG;
  GPIO_InitStruct.Pull = GPIO_NOPULL;
  HAL_GPIO_Init(GPIOB, &GPIO_InitStruct);

  /*Configure GPIO pin : PA8 */
  GPIO_InitStruct.Pin = GPIO_PIN_8;
  GPIO_InitStruct.Mode = GPIO_MODE_ANALOG;
  GPIO_InitStruct.Pull = GPIO_NOPULL;
  HAL_GPIO_Init(GPIOA, &GPIO_InitStruct);

}

void Error_Handler(void)
{
  __disable_irq();
  while (1)
  {
  }
}
